AUTOSAR XML (schema 4-2-2)
package /BMW/Platform/Rmh/SwcImplementations
  swc implementation Rmh_Implementation: behavior=InternalBehavior
    code-descriptors:
      code CodeDescriptor: artifact-descriptors=autosar-engineering-object={short-label=Default, category=SWSRC}
package /BMW/Platform/Rmh/SwComponentTypes
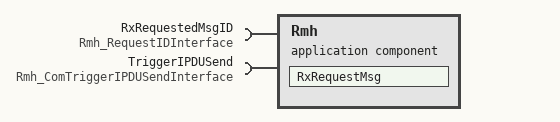
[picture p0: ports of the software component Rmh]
  application sw component type Rmh
    require port RxRequestedMsgID: nonqueued-receiver-com-spec{data-element=requestedMsgID, filter=data-filter-type=ALWAYS, init-value=0xFFFF}, required-interface=Rmh_RequestIDInterface
    require port TriggerIPDUSend: client-com-spec=Rmh_TriggerComIPDUSend, required-interface=Rmh_ComTriggerIPDUSendInterface
    behavior InternalBehavior
      data received event DataReceivedEvent: start-on-event=RxRequestMsg, data=RxRequestedMsgID.requestedMsgID
      port-api-options:
        enable-take-address=false, error-handling=NO-TRANSFORMER-ERROR-HANDLING, indirect-api=false, port=RxRequestedMsgID
        enable-take-address=false, error-handling=NO-TRANSFORMER-ERROR-HANDLING, indirect-api=false, port=TriggerIPDUSend
      runnable RxRequestMsg: symbol=Rmh_RxRequestMsg
        data-receive-point-by-arguments:
          access dra_RxRequestedMsgID: accessed-variable=RxRequestedMsgID.requestedMsgID
        sync call sscp_TriggerIPDUSend: operation=TriggerIPDUSend.Rmh_TriggerComIPDUSend, timeout=0
